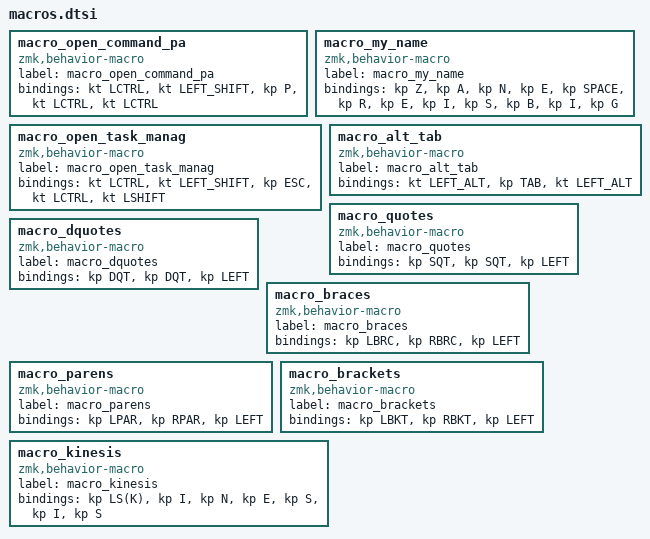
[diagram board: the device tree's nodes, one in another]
macro_open_command_pa: macro_open_command_pa{
compatible = "zmk,behavior-macro";
label = "macro_open_command_pa";
#binding-cells = <0>;
bindings = <&kt LCTRL>, <&kt LEFT_SHIFT>, <&kp P>, <&kt LCTRL>, <&kt LCTRL>;
};
macro_my_name: macro_my_name{
compatible = "zmk,behavior-macro";
label = "macro_my_name";
#binding-cells = <0>;
bindings = <&kp Z>, <&kp A>, <&kp N>, <&kp E>, <&kp SPACE>, <&kp R>, <&kp E>, <&kp I>, <&kp S>, <&kp B>, <&kp I>, <&kp G>;
};
macro_open_task_manag: macro_open_task_manag{
compatible = "zmk,behavior-macro";
label = "macro_open_task_manag";
#binding-cells = <0>;
bindings = <&kt LCTRL>, <&kt LEFT_SHIFT>, <&kp ESC>, <&kt LCTRL>, <&kt LSHIFT>;
};
macro_alt_tab: macro_alt_tab{
compatible = "zmk,behavior-macro";
label = "macro_alt_tab";
#binding-cells = <0>;
bindings = <&kt LEFT_ALT>, <&kp TAB>, <&kt LEFT_ALT>;
};
macro_quotes: macro_quotes{
compatible = "zmk,behavior-macro";
label = "macro_quotes";
#binding-cells = <0>;
bindings = <&kp SQT>, <&kp SQT>, <&kp LEFT>;
};
macro_dquotes: macro_dquotes{
compatible = "zmk,behavior-macro";
label = "macro_dquotes";
#binding-cells = <0>;
bindings = <&kp DQT>, <&kp DQT>, <&kp LEFT>;
};
macro_braces: macro_braces{
compatible = "zmk,behavior-macro";
label = "macro_braces";
#binding-cells = <0>;
bindings = <&kp LBRC>, <&kp RBRC>, <&kp LEFT>;
};
macro_parens: macro_parens{
compatible = "zmk,behavior-macro";
label = "macro_parens";
#binding-cells = <0>;
bindings = <&kp LPAR>, <&kp RPAR>, <&kp LEFT>;
};
macro_brackets: macro_brackets{
compatible = "zmk,behavior-macro";
label = "macro_brackets";
#binding-cells = <0>;
bindings = <&kp LBKT>, <&kp RBKT>, <&kp LEFT>;
};
macro_kinesis: macro_kinesis{
compatible = "zmk,behavior-macro";
label = "macro_kinesis";
#binding-cells = <0>;
bindings = <&kp LS(K)>, <&kp I>, <&kp N>, <&kp E>, <&kp S>, <&kp I>, <&kp S>;
};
